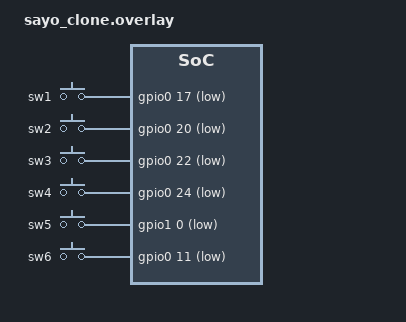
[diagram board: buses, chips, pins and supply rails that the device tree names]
/ {
    keys {
        compatible = "zmk,keys";
        #address-cells = <1>;
        #size-cells = <0>;

        sw1: sw1 {
            gpios = <&gpio0 17 GPIO_ACTIVE_LOW>; /* P0.17 */
        };

        sw2: sw2 {
            gpios = <&gpio0 20 GPIO_ACTIVE_LOW>; /* P0.20 */
        };

        sw3: sw3 {
            gpios = <&gpio0 22 GPIO_ACTIVE_LOW>; /* P0.22 */
        };

        sw4: sw4 {
            gpios = <&gpio0 24 GPIO_ACTIVE_LOW>; /* P0.24 */
        };

        sw5: sw5 {
            gpios = <&gpio1 0 GPIO_ACTIVE_LOW>;  /* P1.00 */
        };

        sw6: sw6 {
            gpios = <&gpio0 11 GPIO_ACTIVE_LOW>; /* P0.11 */
        };
    };
};
